# AT32F426xx_v2 register map
Vendor: Keil; Series: AT32F426; File version: 1.0
CPU: CM4 r0p1, little endian, no MPU, FPU, 4 interrupt priority bits
Registers are 32-bit, read-write, reset 0x0 unless marked. A register's access mark holds for its fields unless they carry their own. Offsets are from the block's base; [hi:lo] are bit positions; {n}, {i} and the like mark numbered series; 'fields as' and 'values as' point back to an identical list.

## DMA1 — DMA controller
Base 0x40020000
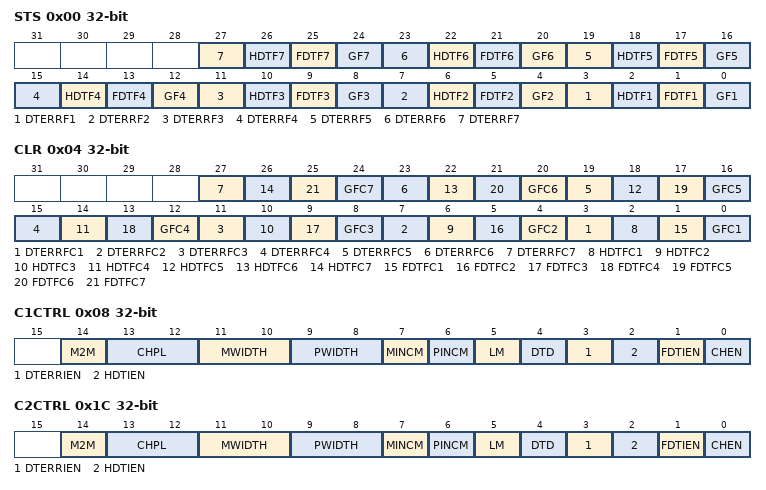
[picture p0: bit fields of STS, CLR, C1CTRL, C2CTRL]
0x00 STS ro — DMA interrupt status register (DMA_STS)
  [4n-1] DTERRF{n} (n=1..7) — Channel {n} data transfer error event flag
  [4n-2] HDTF{n} (n=1..7) — Channel {n} half data transfer event flag
  [4n-3] FDTF{n} (n=1..7) — Channel {n} full data transfer event flag
  [4n-4] GF{n} (n=1..7) — Channel {n} Global event flag
0x04 CLR — DMA interrupt flag clear register (DMA_CLR)
  [4n-1] DTERRFC{n} (n=1..7) — Channel {n} data transfer error flag clear
  [4n-2] HDTFC{n} (n=1..7) — Channel {n} half data transfer flag clear
  [4n-3] FDTFC{n} (n=1..7) — Channel {n} full data transfer flag clear
  [4n-4] GFC{n} (n=1..7) — Channel {n} Global flag clear
0x08 C1CTRL — DMA channel configuration register(DMA_C1CTRL)
  [14] M2M — Memory to memory mode
  [13:12] CHPL — Channel Priority level
  [11:10] MWIDTH — Memory data bit width
  [9:8] PWIDTH — Peripheral data bit width
  [7] MINCM — Memory increment mode
  [6] PINCM — Peripheral increment mode
  [5] LM — Loop mode
  [4] DTD — Data transfer direction
  [3] DTERRIEN — Transfer error interrupt enable
  [2] HDTIEN — Half transfer interrupt enable
  [1] FDTIEN — Transfer complete interrupt enable
  [0] CHEN — Channel enable
0x0C C1DTCNT — DMA channel 1 number of data to transfer register
  [15:0] CNT — Number of data to transfer
0x10 C1PADDR — DMA channel 1 peripheral base address register
  [31:0] PADDR — Peripheral address
{0x0+0x14*i} C{i}MADDR (i=1..5) — DMA channel {i} memory base address register
  [31:0] MADDR — Memory address
0x1C C2CTRL — DMA channel configuration register (DMA_C2CTRL)
  fields as C1CTRL
0x20 C2DTCNT — DMA channel 2 number of data to transferregister
  [15:0] CNT — Number of data to transfer
0x24 C2PADDR — DMA channel 2 peripheral base address register
  [31:0] PADDR — Peripheral address
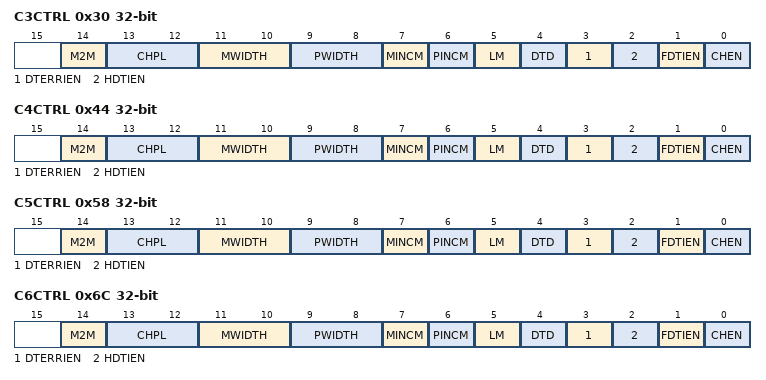
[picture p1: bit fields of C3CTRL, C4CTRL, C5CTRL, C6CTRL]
0x30 C3CTRL — DMA channel configuration register (DMA_C3CTRL)
  fields as C1CTRL
0x34 C3DTCNT — DMA channel 3 number of data to transfer register
  [15:0] CNT — Number of data to transfer
0x38 C3PADDR — DMA channel 3 peripheral base address register
  [31:0] PADDR — Peripheral address
0x44 C4CTRL — DMA channel configuration register (DMA_C4CTRL)
  fields as C1CTRL
0x48 C4DTCNT — DMA channel 4 number of data to transfer register
  [15:0] CNT — Number of data to transfer
0x4C C4PADDR — DMA channel 4 peripheral base address register
  [31:0] PADDR — Peripheral address
0x58 C5CTRL — DMA channel configuration register (DMA_C5CTRL)
  fields as C1CTRL
0x5C C5DTCNT — DMA channel 5 number of data to transfer register
  [15:0] CNT — Number of data to transfer
0x60 C5PADDR — DMA channel 5 peripheral base address register
  [31:0] PADDR — Peripheral address
0x6C C6CTRL — DMA channel configuration register(DMA_C6CTRL)
  fields as C1CTRL
0x70 C6DTCNT — DMA channel 6 number of data to transfer register
  [15:0] CNT — Number of data to transfer
0x74 C6PADDR — DMA channel 6 peripheral address base register
  [31:0] PADDR — Peripheral address
0x78 C6MADDR — DMA channel 6 memory address base register
  [31:0] MADDR — Memory address
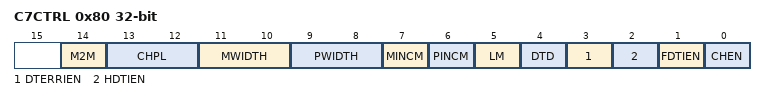
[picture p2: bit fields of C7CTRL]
0x80 C7CTRL — DMA channel configuration register(DMA_C7CTRL)
  fields as C1CTRL
0x84 C7DTCNT — DMA channel 7 number of data to transfer register
  [15:0] CNT — Number of data to transfer
0x88 C7PADDR — DMA channel 7 peripheral base address register
  [31:0] PADDR — Peripheral address
0x8C C7MADDR — DMA channel 7 memory base address register
  [31:0] MADDR — Memory address

## ERTC — Real-time clock
Base 0x40002800
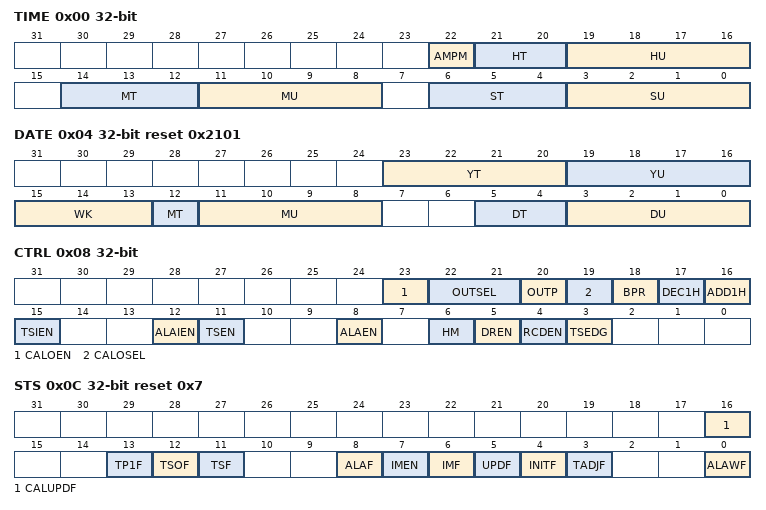
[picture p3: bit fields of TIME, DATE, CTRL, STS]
0x00 TIME
  [22] AMPM — AM/PM notation
  [21:20] HT — Hour tens
  [19:16] HU — Hour units
  [14:12] MT — Minute tens
  [11:8] MU — Minute units
  [6:4] ST — Second tens
  [3:0] SU — Second units
0x04 DATE reset 0x2101
  [23:20] YT — Year tens
  [19:16] YU — Year units
  [15:13] WK — Week
  [12] MT — Month tens
  [11:8] MU — Month units
  [5:4] DT — Date tens
  [3:0] DU — Date units
0x08 CTRL — control register
  [23] CALOEN — Calibration output enable
  [22:21] OUTSEL — Output source selection
  [20] OUTP — Output polarity
  [19] CALOSEL — Calibration output selection
  [18] BPR — Battery power domain data register
  [17] DEC1H — Decrease 1 hour
  [16] ADD1H — Add 1 hour
  [15] TSIEN — Timestamp interrupt enable
  [12] ALAIEN — Alarm A interrupt enable
  [11] TSEN — Timestamp enable
  [8] ALAEN — Alarm A enable
  [6] HM — Hour mode
  [5] DREN — Date/time register direct read enable
  [4] RCDEN — Reference clock detection enable
  [3] TSEDG — Timestamp trigger edge
0x0C STS reset 0x7 — initialization and status register
  [16] CALUPDF ro — Calibration value update completed flag
  [13] TP1F — Tamper detection 1 flag
  [12] TSOF — Timestamp overflow flag
  [11] TSF — Timestamp flag
  [8] ALAF — Alarm A flag
  [7] IMEN — Initialization mode enable
  [6] IMF ro — Enter initialization mode flag
  [5] UPDF — Calendar update flag
  [4] INITF ro — Calendar initialization flag
  [3] TADJF — Time adjustment flag
  [0] ALAWF ro — Alarm A register allows write flag
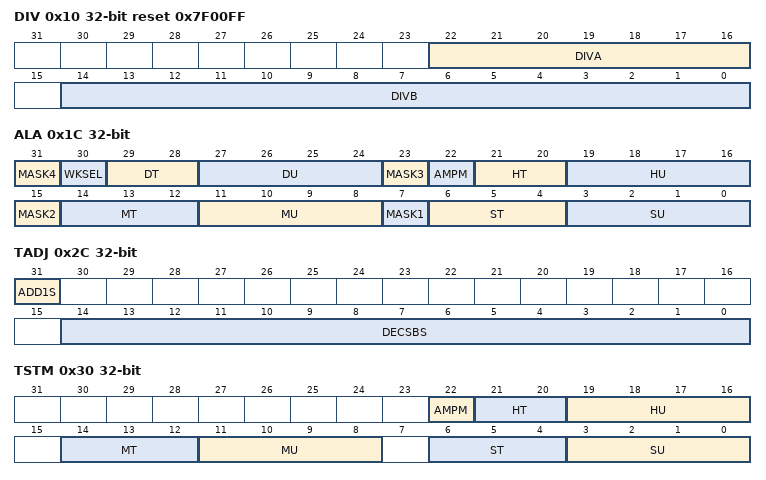
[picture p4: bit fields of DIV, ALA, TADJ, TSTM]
0x10 DIV reset 0x7F00FF — Diveder register
  [22:16] DIVA — Diveder A
  [14:0] DIVB — Diveder B
0x1C ALA — Alarm A register
  [31] MASK4 — Date/week mask
  [30] WKSEL — Date/week mode select
  [29:28] DT — Date tens
  [27:24] DU — Date units
  [23] MASK3 — Hours mask
  [22] AMPM
  [21:20] HT — Hour tens
  [19:16] HU — Hour units
  [15] MASK2 — Minutes mask
  [14:12] MT — Minute tens
  [11:8] MU — Minute units
  [7] MASK1 — Seconds mask
  [6:4] ST — Second tens
  [3:0] SU — Second units
0x24 WP wo — write protection register
  [7:0] CMD — Command register
0x28 SBS ro — sub second register
  [15:0] SBS — Sub second value
0x2C TADJ wo — time adjust register
  [31] ADD1S — Add 1 second
  [14:0] DECSBS — Decrease sub-second value
0x30 TSTM ro — time stamp time register
  [22] AMPM
  [21:20] HT — Hour tens
  [19:16] HU — Hour units
  [14:12] MT — Minute tens
  [11:8] MU — Minute units
  [6:4] ST — Second tens
  [3:0] SU — Second units
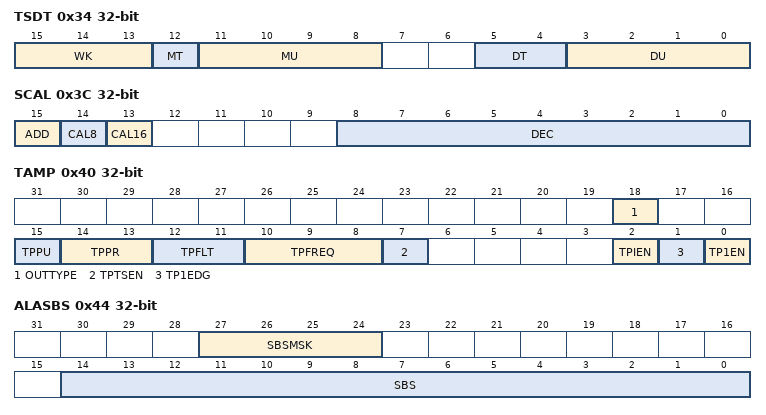
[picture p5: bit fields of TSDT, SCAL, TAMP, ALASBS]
0x34 TSDT ro — timestamp date register
  [15:13] WK — Week
  [12] MT — Month tens
  [11:8] MU — Month units
  [5:4] DT — Date tens
  [3:0] DU — Date units
0x38 TSSBS ro — timestamp sub second register
  [15:0] SBS — Sub second value
0x3C SCAL — calibration register
  [15] ADD — Add ERTC clock
  [14] CAL8 — 8-second calibration period
  [13] CAL16 — 16 second calibration period
  [8:0] DEC — Decrease ERTC clock
0x40 TAMP — tamper and alternate function configuration register
  [18] OUTTYPE — Output type
  [15] TPPU — Tamper detection pull-up
  [14:13] TPPR — Tamper detection pre-charge time
  [12:11] TPFLT — Tamper detection filter time
  [10:8] TPFREQ — Tamper detection frequency
  [7] TPTSEN — Tamper detection timestamp enable
  [2] TPIEN — Tamper detection interrupt enable
  [1] TP1EDG — Tamper detection 1 valid edge
  [0] TP1EN — Tamper detection 1 enable
0x44 ALASBS — alarm A sub second register
  [27:24] SBSMSK — Sub-second mask
  [14:0] SBS — Sub-seconds value
{0x4C+4i} BPR{i}DT (i=1..5) — Battery powered domain register
  [31:0] DT — Battery powered domain data
